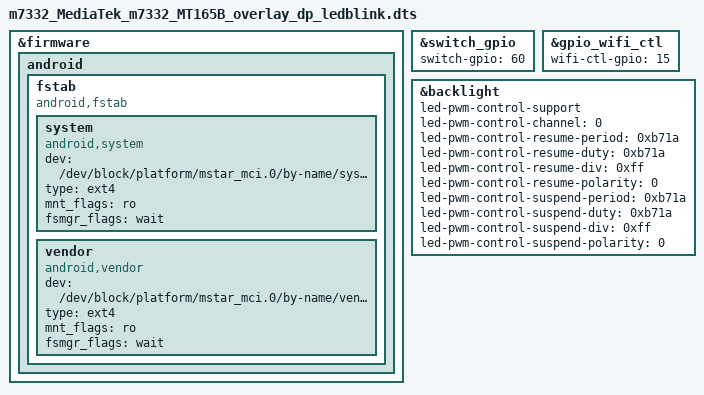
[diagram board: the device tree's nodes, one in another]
/dts-v1/;
/plugin/;

&firmware {
	android {
		fstab {
			compatible = "android,fstab";
			system {
				compatible = "android,system";
				dev = "/dev/block/platform/mstar_mci.0/by-name/system";
				type = "ext4";
				mnt_flags = "ro";
				fsmgr_flags = "wait";
			};
			vendor {
				compatible = "android,vendor";
				dev = "/dev/block/platform/mstar_mci.0/by-name/vendor";
				type = "ext4";
				mnt_flags = "ro";
				fsmgr_flags = "wait";
			};
		};
	};
};

&switch_gpio {
	switch-gpio = <60>;
};

&gpio_wifi_ctl {
	wifi-ctl-gpio = <15>;
};

&backlight {
	led-pwm-control-support;
	led-pwm-control-channel = <0>;
	led-pwm-control-resume-period = <0xb71a>;
	led-pwm-control-resume-duty = <0xb71a>;
	led-pwm-control-resume-div = <0xff>;
	led-pwm-control-resume-polarity = <0>;
	led-pwm-control-suspend-period = <0xb71a>;
	led-pwm-control-suspend-duty = <0xb71a>;
	led-pwm-control-suspend-div = <0xff>;
	led-pwm-control-suspend-polarity = <0>;
};
